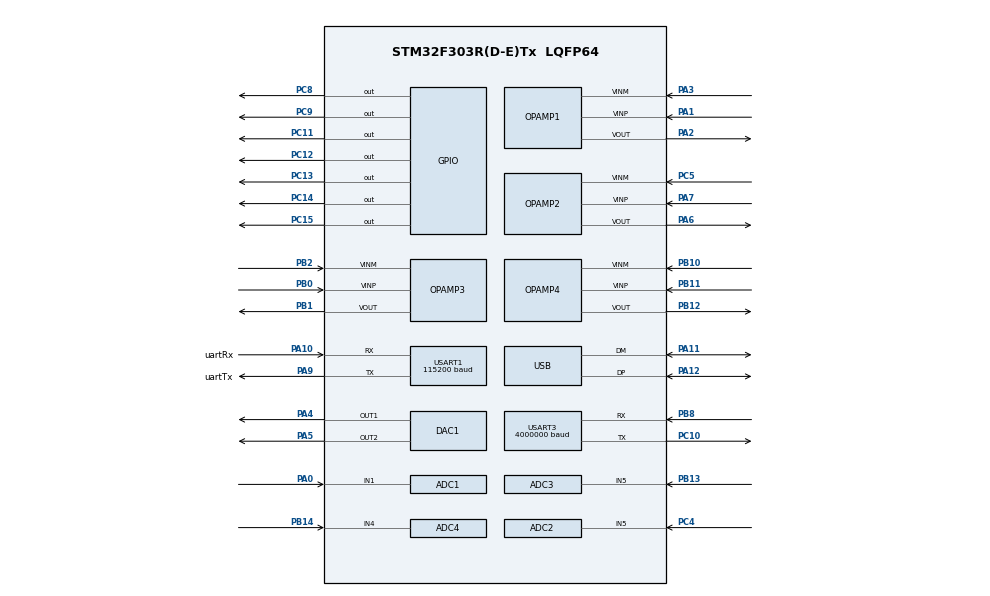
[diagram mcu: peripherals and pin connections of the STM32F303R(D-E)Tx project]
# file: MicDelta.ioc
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ADC1.AWD1HighThreshold=2500
ADC1.AWD1ITMode=ENABLE
ADC1.AWD1LowThreshold=1500
ADC1.Channel-0\#ChannelRegularConversion=ADC_CHANNEL_3
ADC1.ClockPrescaler=ADC_CLOCK_SYNC_PCLK_DIV1
ADC1.ContinuousConvMode=DISABLE
ADC1.DMAContinuousRequests=ENABLE
ADC1.DataAlign=ADC_DATAALIGN_RIGHT
ADC1.DiscontinuousConvMode=DISABLE
ADC1.EOCSelection=ADC_EOC_SINGLE_CONV
ADC1.EnableAnalogWatchDog1=true
ADC1.EnableAnalogWatchDog2=false
ADC1.EnableAnalogWatchDog3=false
ADC1.EnableInjectedConversion=ENABLE
ADC1.EnableRegularConversion=ENABLE
ADC1.ExternalTrigConv=ADC_EXTERNALTRIGCONV_T3_TRGO
ADC1.ExternalTrigConvEdge=ADC_EXTERNALTRIGCONVEDGE_RISING
ADC1.InjNumberOfConversion=0
ADC1.LowPowerAutoWait=DISABLE
ADC1.NbrOfConversion=1
ADC1.NbrOfConversionFlag=1
ADC1.Offset-0\#ChannelRegularConversion=0
ADC1.OffsetNumber-0\#ChannelRegularConversion=ADC_OFFSET_NONE
ADC1.Overrun=ADC_OVR_DATA_OVERWRITTEN
ADC1.Rank-0\#ChannelRegularConversion=1
ADC1.Resolution=ADC_RESOLUTION_12B
ADC1.SamplingTime-0\#ChannelRegularConversion=ADC_SAMPLETIME_61CYCLES_5
ADC1.ScanConvMode=ADC_SCAN_DISABLE
ADC1.WatchdogChannel=ADC_CHANNEL_3
ADC1.WatchdogMode=ADC_ANALOGWATCHDOG_SINGLE_REG
ADC1.master=1
ADC2.AWD1HighThreshold=2500
ADC2.AWD1ITMode=ENABLE
ADC2.AWD1LowThreshold=1500
ADC2.Channel-0\#ChannelRegularConversion=ADC_CHANNEL_3
ADC2.ClockPrescaler=ADC_CLOCK_SYNC_PCLK_DIV1
ADC2.ContinuousConvMode=DISABLE
ADC2.DMAContinuousRequests=ENABLE
ADC2.DataAlign=ADC_DATAALIGN_RIGHT
ADC2.DiscontinuousConvMode=DISABLE
ADC2.EOCSelection=ADC_EOC_SINGLE_CONV
ADC2.EnableAnalogWatchDog1=true
ADC2.EnableAnalogWatchDog2=false
ADC2.EnableAnalogWatchDog3=false
ADC2.EnableInjectedConversion=ENABLE
ADC2.EnableRegularConversion=ENABLE
ADC2.ExternalTrigConv=ADC_EXTERNALTRIGCONV_T3_TRGO
ADC2.ExternalTrigConvEdge=ADC_EXTERNALTRIGCONVEDGE_RISING
ADC2.InjNumberOfConversion=0
ADC2.LowPowerAutoWait=DISABLE
ADC2.NbrOfConversion=1
ADC2.NbrOfConversionFlag=1
ADC2.Offset-0\#ChannelRegularConversion=0
ADC2.OffsetNumber-0\#ChannelRegularConversion=ADC_OFFSET_NONE
ADC2.Overrun=ADC_OVR_DATA_OVERWRITTEN
ADC2.Rank-0\#ChannelRegularConversion=1
ADC2.Resolution=ADC_RESOLUTION_12B
ADC2.SamplingTime-0\#ChannelRegularConversion=ADC_SAMPLETIME_61CYCLES_5
ADC2.ScanConvMode=ADC_SCAN_DISABLE
ADC2.WatchdogChannel=ADC_CHANNEL_3
ADC2.WatchdogMode=ADC_ANALOGWATCHDOG_SINGLE_REG
ADC3.AWD1HighThreshold=2500
ADC3.AWD1ITMode=ENABLE
ADC3.AWD1LowThreshold=1500
ADC3.Channel-44\#ChannelRegularConversion=ADC_CHANNEL_1
ADC3.ClockPrescaler=ADC_CLOCK_SYNC_PCLK_DIV1
ADC3.ContinuousConvMode=DISABLE
ADC3.DMAContinuousRequests=ENABLE
ADC3.DataAlign=ADC_DATAALIGN_RIGHT
ADC3.DiscontinuousConvMode=DISABLE
ADC3.EOCSelection=ADC_EOC_SINGLE_CONV
ADC3.EnableAnalogWatchDog1=true
ADC3.EnableAnalogWatchDog2=false
ADC3.EnableAnalogWatchDog3=false
ADC3.EnableInjectedConversion=ENABLE
ADC3.EnableRegularConversion=ENABLE
ADC3.ExternalTrigConv=ADC_EXTERNALTRIGCONV_T3_TRGO
ADC3.ExternalTrigConvEdge=ADC_EXTERNALTRIGCONVEDGE_RISING
ADC3.InjNumberOfConversion=0
ADC3.LowPowerAutoWait=DISABLE
ADC3.NbrOfConversion=1
ADC3.NbrOfConversionFlag=1
ADC3.Offset-44\#ChannelRegularConversion=0
ADC3.OffsetNumber-44\#ChannelRegularConversion=ADC_OFFSET_NONE
ADC3.Overrun=ADC_OVR_DATA_OVERWRITTEN
ADC3.Rank-44\#ChannelRegularConversion=1
ADC3.Resolution=ADC_RESOLUTION_12B
ADC3.SamplingTime-44\#ChannelRegularConversion=ADC_SAMPLETIME_61CYCLES_5
ADC3.ScanConvMode=ADC_SCAN_DISABLE
ADC3.WatchdogChannel=ADC_CHANNEL_1
ADC3.WatchdogMode=ADC_ANALOGWATCHDOG_SINGLE_REG
ADC3.master=1
ADC4.AWD1HighThreshold=2500
ADC4.AWD1ITMode=ENABLE
ADC4.AWD1LowThreshold=1500
ADC4.Channel-56\#ChannelRegularConversion=ADC_CHANNEL_3
ADC4.ClockPrescaler=ADC_CLOCK_SYNC_PCLK_DIV1
ADC4.ContinuousConvMode=DISABLE
ADC4.DMAContinuousRequests=ENABLE
ADC4.DataAlign=ADC_DATAALIGN_RIGHT
ADC4.DiscontinuousConvMode=DISABLE
ADC4.EOCSelection=ADC_EOC_SINGLE_CONV
ADC4.EnableAnalogWatchDog1=true
ADC4.EnableAnalogWatchDog2=false
ADC4.EnableAnalogWatchDog3=false
ADC4.EnableInjectedConversion=ENABLE
ADC4.EnableRegularConversion=ENABLE
ADC4.ExternalTrigConv=ADC_EXTERNALTRIGCONV_T3_TRGO
ADC4.ExternalTrigConvEdge=ADC_EXTERNALTRIGCONVEDGE_RISING
ADC4.InjNumberOfConversion=0
ADC4.LowPowerAutoWait=DISABLE
ADC4.NbrOfConversion=1
ADC4.NbrOfConversionFlag=1
ADC4.Offset-56\#ChannelRegularConversion=0
ADC4.OffsetNumber-56\#ChannelRegularConversion=ADC_OFFSET_NONE
ADC4.Overrun=ADC_OVR_DATA_OVERWRITTEN
ADC4.Rank-56\#ChannelRegularConversion=1
ADC4.Resolution=ADC_RESOLUTION_12B
ADC4.SamplingTime-56\#ChannelRegularConversion=ADC_SAMPLETIME_61CYCLES_5
ADC4.ScanConvMode=ADC_SCAN_DISABLE
ADC4.WatchdogChannel=ADC_CHANNEL_3
ADC4.WatchdogMode=ADC_ANALOGWATCHDOG_SINGLE_REG
ARM.CMSIS.5.6.0.CMSISJjDSP=Library
Dma.ADC1.7.Direction=DMA_PERIPH_TO_MEMORY
Dma.ADC1.7.Instance=DMA1_Channel1
Dma.ADC1.7.MemDataAlignment=DMA_MDATAALIGN_HALFWORD
Dma.ADC1.7.MemInc=DMA_MINC_ENABLE
Dma.ADC1.7.Mode=DMA_CIRCULAR
Dma.ADC1.7.PeriphDataAlignment=DMA_PDATAALIGN_HALFWORD
Dma.ADC1.7.PeriphInc=DMA_PINC_DISABLE
Dma.ADC1.7.Priority=DMA_PRIORITY_MEDIUM
Dma.ADC2.5.Direction=DMA_PERIPH_TO_MEMORY
Dma.ADC2.5.Instance=DMA2_Channel1
Dma.ADC2.5.MemDataAlignment=DMA_MDATAALIGN_HALFWORD
Dma.ADC2.5.MemInc=DMA_MINC_ENABLE
Dma.ADC2.5.Mode=DMA_CIRCULAR
Dma.ADC2.5.PeriphDataAlignment=DMA_PDATAALIGN_HALFWORD
Dma.ADC2.5.PeriphInc=DMA_PINC_DISABLE
Dma.ADC2.5.Priority=DMA_PRIORITY_MEDIUM
Dma.ADC3.4.Direction=DMA_PERIPH_TO_MEMORY
Dma.ADC3.4.Instance=DMA2_Channel5
Dma.ADC3.4.MemDataAlignment=DMA_MDATAALIGN_HALFWORD
Dma.ADC3.4.MemInc=DMA_MINC_ENABLE
Dma.ADC3.4.Mode=DMA_CIRCULAR
Dma.ADC3.4.PeriphDataAlignment=DMA_PDATAALIGN_HALFWORD
Dma.ADC3.4.PeriphInc=DMA_PINC_DISABLE
Dma.ADC3.4.Priority=DMA_PRIORITY_MEDIUM
Dma.ADC4.3.Direction=DMA_PERIPH_TO_MEMORY
Dma.ADC4.3.Instance=DMA2_Channel2
Dma.ADC4.3.MemDataAlignment=DMA_MDATAALIGN_HALFWORD
Dma.ADC4.3.MemInc=DMA_MINC_ENABLE
Dma.ADC4.3.Mode=DMA_CIRCULAR
Dma.ADC4.3.PeriphDataAlignment=DMA_PDATAALIGN_HALFWORD
Dma.ADC4.3.PeriphInc=DMA_PINC_DISABLE
Dma.ADC4.3.Priority=DMA_PRIORITY_MEDIUM
Dma.MEMTOMEM.0.Direction=DMA_MEMORY_TO_MEMORY
Dma.MEMTOMEM.0.Instance=DMA1_Channel3
Dma.MEMTOMEM.0.MemDataAlignment=DMA_MDATAALIGN_BYTE
Dma.MEMTOMEM.0.MemInc=DMA_MINC_ENABLE
Dma.MEMTOMEM.0.Mode=DMA_NORMAL
Dma.MEMTOMEM.0.PeriphDataAlignment=DMA_PDATAALIGN_BYTE
Dma.MEMTOMEM.0.PeriphInc=DMA_PINC_ENABLE
Dma.MEMTOMEM.0.Priority=DMA_PRIORITY_LOW
Dma.Request0=MEMTOMEM
Dma.Request1=USART1_TX
Dma.Request2=USART1_RX
Dma.Request3=ADC4
Dma.Request4=ADC3
Dma.Request5=ADC2
Dma.Request6=TIM4_UP
Dma.Request7=ADC1
Dma.Request8=USART3_TX
Dma.TIM4_UP.6.Direction=DMA_MEMORY_TO_PERIPH
Dma.TIM4_UP.6.Instance=DMA1_Channel7
Dma.TIM4_UP.6.MemDataAlignment=DMA_MDATAALIGN_BYTE
Dma.TIM4_UP.6.MemInc=DMA_MINC_ENABLE
Dma.TIM4_UP.6.Mode=DMA_NORMAL
Dma.TIM4_UP.6.PeriphDataAlignment=DMA_PDATAALIGN_BYTE
Dma.TIM4_UP.6.PeriphInc=DMA_PINC_DISABLE
Dma.TIM4_UP.6.Priority=DMA_PRIORITY_VERY_HIGH
Dma.USART1_RX.2.Direction=DMA_PERIPH_TO_MEMORY
Dma.USART1_RX.2.Instance=DMA1_Channel5
Dma.USART1_RX.2.MemDataAlignment=DMA_MDATAALIGN_BYTE
Dma.USART1_RX.2.MemInc=DMA_MINC_ENABLE
Dma.USART1_RX.2.Mode=DMA_CIRCULAR
Dma.USART1_RX.2.PeriphDataAlignment=DMA_PDATAALIGN_BYTE
Dma.USART1_RX.2.PeriphInc=DMA_PINC_DISABLE
Dma.USART1_RX.2.Priority=DMA_PRIORITY_LOW
Dma.USART1_TX.1.Direction=DMA_MEMORY_TO_PERIPH
Dma.USART1_TX.1.Instance=DMA1_Channel4
Dma.USART1_TX.1.MemDataAlignment=DMA_MDATAALIGN_BYTE
Dma.USART1_TX.1.MemInc=DMA_MINC_ENABLE
Dma.USART1_TX.1.Mode=DMA_NORMAL
Dma.USART1_TX.1.PeriphDataAlignment=DMA_PDATAALIGN_BYTE
Dma.USART1_TX.1.PeriphInc=DMA_PINC_DISABLE
Dma.USART1_TX.1.Priority=DMA_PRIORITY_LOW
Dma.USART3_TX.8.Direction=DMA_MEMORY_TO_PERIPH
Dma.USART3_TX.8.Instance=DMA1_Channel2
Dma.USART3_TX.8.MemDataAlignment=DMA_MDATAALIGN_BYTE
Dma.USART3_TX.8.MemInc=DMA_MINC_ENABLE
Dma.USART3_TX.8.Mode=DMA_NORMAL
Dma.USART3_TX.8.PeriphDataAlignment=DMA_PDATAALIGN_BYTE
Dma.USART3_TX.8.PeriphInc=DMA_PINC_DISABLE
Dma.USART3_TX.8.Priority=DMA_PRIORITY_HIGH
Mcu.Family=STM32F3
Mcu.Name=STM32F303R(D-E)Tx
Mcu.Package=LQFP64
NVIC.ADC1_2_IRQn=true\:0\:0\:false\:false\:true\:true\:true
NVIC.ADC3_IRQn=true\:0\:0\:false\:false\:true\:true\:true
NVIC.ADC4_IRQn=true\:0\:0\:false\:false\:true\:true\:true
NVIC.DMA1_Channel1_IRQn=true\:0\:0\:false\:false\:true\:false\:true
NVIC.DMA1_Channel2_IRQn=true\:0\:0\:false\:false\:true\:false\:true
NVIC.DMA1_Channel4_IRQn=true\:0\:0\:false\:false\:true\:false\:true
NVIC.DMA1_Channel5_IRQn=true\:0\:0\:false\:false\:true\:false\:true
NVIC.DMA1_Channel7_IRQn=true\:0\:0\:false\:false\:true\:false\:true
NVIC.DMA2_Channel1_IRQn=true\:0\:0\:false\:false\:true\:false\:true
NVIC.DMA2_Channel2_IRQn=true\:0\:0\:false\:false\:true\:false\:true
NVIC.DMA2_Channel5_IRQn=true\:0\:0\:false\:false\:true\:false\:true
NVIC.PriorityGroup=NVIC_PRIORITYGROUP_4
NVIC.TIM2_IRQn=true\:0\:0\:false\:false\:true\:true\:true
NVIC.USART1_IRQn=true\:0\:0\:false\:false\:true\:true\:true
NVIC.USB_LP_CAN_RX0_IRQn=true\:0\:0\:false\:false\:true\:false\:true
OPAMP1.PgaGain=OPAMP_PGA_GAIN_16
OPAMP2.PgaGain=OPAMP_PGA_GAIN_16
OPAMP3.PgaGain=OPAMP_PGA_GAIN_16
OPAMP4.PgaGain=OPAMP_PGA_GAIN_16
PA0.Mode=IN1-Single-Ended
PA0.Signal=ADC1_IN1
PA1.Mode=PGA Connected
PA1.Signal=OPAMP1_VINP
PA10.GPIO_Label=uartRx
PA10.Mode=Asynchronous
PA10.Signal=USART1_RX
PA11.Mode=Device
PA11.Signal=USB_DM
PA12.Mode=Device
PA12.Signal=USB_DP
PA13.Mode=Serial_Wire
PA13.Signal=SYS_JTMS-SWDIO
PA14.Mode=Serial_Wire
PA14.Signal=SYS_JTCK-SWCLK
PA2.Mode=PGA Connected
PA2.Signal=OPAMP1_VOUT
PA3.Mode=PGA Connected
PA3.Signal=OPAMP1_VINM
PA4.Signal=COMP_DAC11_group
PA5.Signal=COMP_DAC12_group
PA6.GPIO_Mode=GPIO_MODE_ANALOG
PA6.Mode=PGA Connected
PA6.Signal=OPAMP2_VOUT
PA7.Mode=PGA Connected
PA7.Signal=OPAMP2_VINP
PA9.GPIO_Label=uartTx
PA9.Mode=Asynchronous
PA9.Signal=USART1_TX
PB0.Mode=PGA Connected
PB0.Signal=OPAMP3_VINP
PB1.Mode=PGA Connected
PB1.Signal=OPAMP3_VOUT
PB10.Mode=PGA Connected
PB10.Signal=OPAMP4_VINM
PB11.Mode=PGA Connected
PB11.Signal=OPAMP4_VINP
PB12.Mode=PGA Connected
PB12.Signal=OPAMP4_VOUT
PB13.Mode=IN5-Single-Ended
PB13.Signal=ADC3_IN5
PB14.Mode=IN4-Single-Ended
PB14.Signal=ADC4_IN4
PB2.Mode=PGA Connected
PB2.Signal=OPAMP3_VINM
PB8.Mode=Asynchronous
PB8.Signal=USART3_RX
PC10.GPIO_Speed=GPIO_SPEED_FREQ_MEDIUM
PC10.Mode=Asynchronous
PC10.Signal=USART3_TX
PC11.Signal=GPIO_Output
PC12.Signal=GPIO_Output
PC13.Signal=GPIO_Output
PC14-OSC32_IN.Signal=GPIO_Output
PC15-OSC32_OUT.Signal=GPIO_Output
PC4.Mode=IN5-Single-Ended
PC4.Signal=ADC2_IN5
PC5.Mode=PGA Connected
PC5.Signal=OPAMP2_VINM
PC8.Signal=GPIO_Output
PC9.Signal=GPIO_Output
PF0-OSC_IN.Mode=HSE-External-Oscillator
PF0-OSC_IN.Signal=RCC_OSC_IN
PF1-OSC_OUT.Mode=HSE-External-Oscillator
PF1-OSC_OUT.Signal=RCC_OSC_OUT
ProjectManager.HeapSize=0x200
ProjectManager.StackSize=0x800
ProjectManager.TargetToolchain=STM32CubeIDE
RCC.AHBFreq_Value=72000000
RCC.APB1CLKDivider=RCC_HCLK_DIV2
RCC.APB1Freq_Value=36000000
RCC.APB1TimFreq_Value=72000000
RCC.APB2Freq_Value=72000000
RCC.APB2TimFreq_Value=72000000
RCC.CortexFreq_Value=72000000
RCC.HCLKFreq_Value=72000000
RCC.HSE_VALUE=8000000
RCC.HSI_VALUE=8000000
RCC.LSE_VALUE=32768
RCC.PLLMUL=RCC_PLL_MUL9
RCC.PRESCALERUSB=RCC_USBCLKSOURCE_PLL_DIV1_5
RCC.SYSCLKFreq_VALUE=72000000
RCC.SYSCLKSourceVirtual=RCC_SYSCLKSOURCE_PLLCLK
RCC.USBFreq_Value=48000000
RCC.Uart4ClockSelection=RCC_UART4CLKSOURCE_SYSCLK
RCC.Uart5ClockSelection=RCC_UART5CLKSOURCE_SYSCLK
RCC.Usart3ClockSelection=RCC_USART3CLKSOURCE_SYSCLK
SH.COMP_DAC11_group.0=DAC1_OUT1,DAC_OUT1
SH.COMP_DAC12_group.0=DAC1_OUT2,Enable_DAC_OUT2
TIM2.AutoReloadPreload=TIM_AUTORELOAD_PRELOAD_ENABLE
TIM2.Period=0xffffffff
TIM2.Prescaler=71
TIM2.TIM_MasterOutputTrigger=TIM_TRGO_UPDATE
TIM3.AutoReloadPreload=TIM_AUTORELOAD_PRELOAD_ENABLE
TIM3.Period=719
TIM3.TIM_MasterOutputTrigger=TIM_TRGO_UPDATE
TIM4.AutoReloadPreload=TIM_AUTORELOAD_PRELOAD_ENABLE
TIM4.Period=28
TIM4.TIM_MasterOutputTrigger=TIM_TRGO_UPDATE
USART1.BaudRate=115200
USART1.VirtualMode-Asynchronous=VM_ASYNC
USART1.WordLength=WORDLENGTH_8B
USART3.BaudRate=4000000
USART3.Mode=MODE_TX
USART3.TxPinLevelInvertParam=ADVFEATURE_TXINV_ENABLE
USART3.VirtualMode-Asynchronous=VM_ASYNC
USB_DEVICE.CLASS_NAME_FS=CDC
USB_DEVICE.VirtualMode=Cdc
USB_DEVICE.VirtualModeFS=Cdc_FS
VP_ADC1_OPAMP_OUT1.Mode=IN3-OPAMP1-Single-Ended
VP_ADC2_OPAMP_OUT2.Mode=IN3-OPAMP2-Single-Ended
VP_ADC3_OPAMP_OUT3.Mode=IN1-OPAMP3-Single-Ended
VP_ADC4_OPAMP_OUT4.Mode=IN3-OPAMP4-Single-Ended
VP_ARM.CMSIS_VS_CMSISJjDSP_1.7.0_5.6.0.Mode=CMSISJjDSP
VP_TIM2_VS_ClockSourceINT.Mode=Internal
VP_TIM3_VS_ClockSourceINT.Mode=Internal
VP_TIM4_VS_ClockSourceINT.Mode=Internal
VP_USB_DEVICE_VS_USB_DEVICE_CDC_FS.Mode=CDC_FS
board=controller

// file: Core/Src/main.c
/* USER CODE BEGIN Header */
/**
  ******************************************************************************
  * @file           : main.c
  * @brief          : Main program body
  ******************************************************************************
  * @attention
  *
  * Copyright (c) 2022 STMicroelectronics.
  * All rights reserved.
  *
  * This software is licensed under terms that can be found in the LICENSE file
  * in the root directory of this software component.
  * If no LICENSE file comes with this software, it is provided AS-IS.
  *
  ******************************************************************************
  */
/* USER CODE END Header */
#include "main.h"
#include "usb_device.h"

ADC_HandleTypeDef hadc1;
ADC_HandleTypeDef hadc2;
ADC_HandleTypeDef hadc3;
ADC_HandleTypeDef hadc4;
DMA_HandleTypeDef hdma_adc1;
DMA_HandleTypeDef hdma_adc2;
DMA_HandleTypeDef hdma_adc3;
DMA_HandleTypeDef hdma_adc4;

OPAMP_HandleTypeDef hopamp1;
OPAMP_HandleTypeDef hopamp2;
OPAMP_HandleTypeDef hopamp3;
OPAMP_HandleTypeDef hopamp4;

void SystemClock_Config(void);
static void MX_GPIO_Init(void);
static void MX_DMA_Init(void);
static void MX_OPAMP2_Init(void);
static void MX_ADC2_Init(void);
static void MX_TIM3_Init(void);
static void MX_OPAMP4_Init(void);
static void MX_ADC4_Init(void);
static void MX_DAC1_Init(void);
static void MX_OPAMP3_Init(void);
static void MX_ADC1_Init(void);
static void MX_ADC3_Init(void);
static void MX_USART1_UART_Init(void);
static void MX_TIM2_Init(void);
static void MX_TIM4_Init(void);
static void MX_OPAMP1_Init(void);
static void MX_USART3_UART_Init(void);

int main(void)
{

  /* MCU Configuration--------------------------------------------------------*/

  /* Reset of all peripherals, Initializes the Flash interface and the Systick. */
  HAL_Init();

  /* Configure the system clock */
  SystemClock_Config();

  /* Initialize all configured peripherals */
  MX_GPIO_Init();
  MX_DMA_Init();
  MX_OPAMP2_Init();
  MX_ADC2_Init();
  MX_TIM3_Init();
  MX_OPAMP4_Init();
  MX_ADC4_Init();
  MX_DAC1_Init();
  MX_OPAMP3_Init();
  MX_ADC1_Init();
  MX_ADC3_Init();
  MX_USART1_UART_Init();
  MX_TIM2_Init();
  MX_USB_DEVICE_Init();
  MX_TIM4_Init();
  MX_OPAMP1_Init();
  MX_USART3_UART_Init();
  /* USER CODE BEGIN 2 */

  appMain(); //never returns!

  /* USER CODE END 2 */

  /* Infinite loop */

}

void SystemClock_Config(void)
{
  LL_FLASH_SetLatency(LL_FLASH_LATENCY_2);
  while(LL_FLASH_GetLatency()!= LL_FLASH_LATENCY_2)
  {
  }
  LL_RCC_HSE_Enable();

   /* Wait till HSE is ready */
  while(LL_RCC_HSE_IsReady() != 1)
  {

  }
  LL_RCC_PLL_ConfigDomain_SYS(LL_RCC_PLLSOURCE_HSE, LL_RCC_PLL_MUL_9, LL_RCC_PREDIV_DIV_1);
  LL_RCC_PLL_Enable();

   /* Wait till PLL is ready */
  while(LL_RCC_PLL_IsReady() != 1)
  {

  }
  LL_RCC_SetAHBPrescaler(LL_RCC_SYSCLK_DIV_1);
  LL_RCC_SetAPB1Prescaler(LL_RCC_APB1_DIV_2);
  LL_RCC_SetAPB2Prescaler(LL_RCC_APB2_DIV_1);
  LL_RCC_SetSysClkSource(LL_RCC_SYS_CLKSOURCE_PLL);

   /* Wait till System clock is ready */
  while(LL_RCC_GetSysClkSource() != LL_RCC_SYS_CLKSOURCE_STATUS_PLL)
  {

  }
  LL_SetSystemCoreClock(72000000);

   /* Update the time base */
  if (HAL_InitTick (TICK_INT_PRIORITY) != HAL_OK)
  {
    Error_Handler();
  }
  LL_RCC_SetUSARTClockSource(LL_RCC_USART1_CLKSOURCE_PCLK2);
  LL_RCC_SetUSARTClockSource(LL_RCC_USART3_CLKSOURCE_SYSCLK);
  LL_RCC_SetTIMClockSource(LL_RCC_TIM2_CLKSOURCE_PCLK1);
  LL_RCC_SetTIMClockSource(LL_RCC_TIM34_CLKSOURCE_PCLK1);
  LL_RCC_SetUSBClockSource(LL_RCC_USB_CLKSOURCE_PLL_DIV_1_5);
}

static void MX_ADC1_Init(void)
{

  ADC_MultiModeTypeDef multimode = {0};
  ADC_AnalogWDGConfTypeDef AnalogWDGConfig = {0};
  ADC_ChannelConfTypeDef sConfig = {0};

  /** Common config
  */
  hadc1.Instance = ADC1;
  hadc1.Init.ClockPrescaler = ADC_CLOCK_SYNC_PCLK_DIV1;
  hadc1.Init.Resolution = ADC_RESOLUTION_12B;
  hadc1.Init.ScanConvMode = ADC_SCAN_DISABLE;
  hadc1.Init.ContinuousConvMode = DISABLE;
  hadc1.Init.DiscontinuousConvMode = DISABLE;
  hadc1.Init.ExternalTrigConvEdge = ADC_EXTERNALTRIGCONVEDGE_RISING;
  hadc1.Init.ExternalTrigConv = ADC_EXTERNALTRIGCONV_T3_TRGO;
  hadc1.Init.DataAlign = ADC_DATAALIGN_RIGHT;
  hadc1.Init.NbrOfConversion = 1;
  hadc1.Init.DMAContinuousRequests = ENABLE;
  hadc1.Init.EOCSelection = ADC_EOC_SINGLE_CONV;
  hadc1.Init.LowPowerAutoWait = DISABLE;
  hadc1.Init.Overrun = ADC_OVR_DATA_OVERWRITTEN;
  if (HAL_ADC_Init(&hadc1) != HAL_OK)
  {
    Error_Handler();
  }
  /** Configure the ADC multi-mode
  */
  multimode.Mode = ADC_MODE_INDEPENDENT;
  if (HAL_ADCEx_MultiModeConfigChannel(&hadc1, &multimode) != HAL_OK)
  {
    Error_Handler();
  }
  /** Configure Analog WatchDog 1
  */
  AnalogWDGConfig.WatchdogNumber = ADC_ANALOGWATCHDOG_1;
  AnalogWDGConfig.WatchdogMode = ADC_ANALOGWATCHDOG_SINGLE_REG;
  AnalogWDGConfig.HighThreshold = 2500;
  AnalogWDGConfig.LowThreshold = 1500;
  AnalogWDGConfig.Channel = ADC_CHANNEL_3;
  AnalogWDGConfig.ITMode = ENABLE;
  if (HAL_ADC_AnalogWDGConfig(&hadc1, &AnalogWDGConfig) != HAL_OK)
  {
    Error_Handler();
  }
  /** Configure Regular Channel
  */
  sConfig.Channel = ADC_CHANNEL_3;
  sConfig.Rank = ADC_REGULAR_RANK_1;
  sConfig.SingleDiff = ADC_SINGLE_ENDED;
  sConfig.SamplingTime = ADC_SAMPLETIME_61CYCLES_5;
  sConfig.OffsetNumber = ADC_OFFSET_NONE;
  sConfig.Offset = 0;
  if (HAL_ADC_ConfigChannel(&hadc1, &sConfig) != HAL_OK)
  {
    Error_Handler();
  }

}

static void MX_ADC2_Init(void)
{

  ADC_AnalogWDGConfTypeDef AnalogWDGConfig = {0};
  ADC_ChannelConfTypeDef sConfig = {0};

  /** Common config
  */
  hadc2.Instance = ADC2;
  hadc2.Init.ClockPrescaler = ADC_CLOCK_SYNC_PCLK_DIV1;
  hadc2.Init.Resolution = ADC_RESOLUTION_12B;
  hadc2.Init.ScanConvMode = ADC_SCAN_DISABLE;
  hadc2.Init.ContinuousConvMode = DISABLE;
  hadc2.Init.DiscontinuousConvMode = DISABLE;
  hadc2.Init.ExternalTrigConvEdge = ADC_EXTERNALTRIGCONVEDGE_RISING;
  hadc2.Init.ExternalTrigConv = ADC_EXTERNALTRIGCONV_T3_TRGO;
  hadc2.Init.DataAlign = ADC_DATAALIGN_RIGHT;
  hadc2.Init.NbrOfConversion = 1;
  hadc2.Init.DMAContinuousRequests = ENABLE;
  hadc2.Init.EOCSelection = ADC_EOC_SINGLE_CONV;
  hadc2.Init.LowPowerAutoWait = DISABLE;
  hadc2.Init.Overrun = ADC_OVR_DATA_OVERWRITTEN;
  if (HAL_ADC_Init(&hadc2) != HAL_OK)
  {
    Error_Handler();
  }
  /** Configure Analog WatchDog 1
  */
  AnalogWDGConfig.WatchdogNumber = ADC_ANALOGWATCHDOG_1;
  AnalogWDGConfig.WatchdogMode = ADC_ANALOGWATCHDOG_SINGLE_REG;
  AnalogWDGConfig.HighThreshold = 2500;
  AnalogWDGConfig.LowThreshold = 1500;
  AnalogWDGConfig.Channel = ADC_CHANNEL_3;
  AnalogWDGConfig.ITMode = ENABLE;
  if (HAL_ADC_AnalogWDGConfig(&hadc2, &AnalogWDGConfig) != HAL_OK)
  {
    Error_Handler();
  }
  /** Configure Regular Channel
  */
  sConfig.Channel = ADC_CHANNEL_3;
  sConfig.Rank = ADC_REGULAR_RANK_1;
  sConfig.SingleDiff = ADC_SINGLE_ENDED;
  sConfig.SamplingTime = ADC_SAMPLETIME_61CYCLES_5;
  sConfig.OffsetNumber = ADC_OFFSET_NONE;
  sConfig.Offset = 0;
  if (HAL_ADC_ConfigChannel(&hadc2, &sConfig) != HAL_OK)
  {
    Error_Handler();
  }

}

static void MX_ADC3_Init(void)
{

  ADC_MultiModeTypeDef multimode = {0};
  ADC_AnalogWDGConfTypeDef AnalogWDGConfig = {0};
  ADC_ChannelConfTypeDef sConfig = {0};

  /** Common config
  */
  hadc3.Instance = ADC3;
  hadc3.Init.ClockPrescaler = ADC_CLOCK_SYNC_PCLK_DIV1;
  hadc3.Init.Resolution = ADC_RESOLUTION_12B;
  hadc3.Init.ScanConvMode = ADC_SCAN_DISABLE;
  hadc3.Init.ContinuousConvMode = DISABLE;
  hadc3.Init.DiscontinuousConvMode = DISABLE;
  hadc3.Init.ExternalTrigConvEdge = ADC_EXTERNALTRIGCONVEDGE_RISING;
  hadc3.Init.ExternalTrigConv = ADC_EXTERNALTRIGCONV_T3_TRGO;
  hadc3.Init.DataAlign = ADC_DATAALIGN_RIGHT;
  hadc3.Init.NbrOfConversion = 1;
  hadc3.Init.DMAContinuousRequests = ENABLE;
  hadc3.Init.EOCSelection = ADC_EOC_SINGLE_CONV;
  hadc3.Init.LowPowerAutoWait = DISABLE;
  hadc3.Init.Overrun = ADC_OVR_DATA_OVERWRITTEN;
  if (HAL_ADC_Init(&hadc3) != HAL_OK)
  {
    Error_Handler();
  }
  /** Configure the ADC multi-mode
  */
  multimode.Mode = ADC_MODE_INDEPENDENT;
  if (HAL_ADCEx_MultiModeConfigChannel(&hadc3, &multimode) != HAL_OK)
  {
    Error_Handler();
  }
  /** Configure Analog WatchDog 1
  */
  AnalogWDGConfig.WatchdogNumber = ADC_ANALOGWATCHDOG_1;
  AnalogWDGConfig.WatchdogMode = ADC_ANALOGWATCHDOG_SINGLE_REG;
  AnalogWDGConfig.HighThreshold = 2500;
  AnalogWDGConfig.LowThreshold = 1500;
  AnalogWDGConfig.Channel = ADC_CHANNEL_1;
  AnalogWDGConfig.ITMode = ENABLE;
  if (HAL_ADC_AnalogWDGConfig(&hadc3, &AnalogWDGConfig) != HAL_OK)
  {
    Error_Handler();
  }
  /** Configure Regular Channel
  */
  sConfig.Channel = ADC_CHANNEL_1;
  sConfig.Rank = ADC_REGULAR_RANK_1;
  sConfig.SingleDiff = ADC_SINGLE_ENDED;
  sConfig.SamplingTime = ADC_SAMPLETIME_61CYCLES_5;
  sConfig.OffsetNumber = ADC_OFFSET_NONE;
  sConfig.Offset = 0;
  if (HAL_ADC_ConfigChannel(&hadc3, &sConfig) != HAL_OK)
  {
    Error_Handler();
  }

}

static void MX_ADC4_Init(void)
{

  ADC_AnalogWDGConfTypeDef AnalogWDGConfig = {0};
  ADC_ChannelConfTypeDef sConfig = {0};

  /** Common config
  */
  hadc4.Instance = ADC4;
  hadc4.Init.ClockPrescaler = ADC_CLOCK_SYNC_PCLK_DIV1;
  hadc4.Init.Resolution = ADC_RESOLUTION_12B;
  hadc4.Init.ScanConvMode = ADC_SCAN_DISABLE;
  hadc4.Init.ContinuousConvMode = DISABLE;
  hadc4.Init.DiscontinuousConvMode = DISABLE;
  hadc4.Init.ExternalTrigConvEdge = ADC_EXTERNALTRIGCONVEDGE_RISING;
  hadc4.Init.ExternalTrigConv = ADC_EXTERNALTRIGCONV_T3_TRGO;
  hadc4.Init.DataAlign = ADC_DATAALIGN_RIGHT;
  hadc4.Init.NbrOfConversion = 1;
  hadc4.Init.DMAContinuousRequests = ENABLE;
  hadc4.Init.EOCSelection = ADC_EOC_SINGLE_CONV;
  hadc4.Init.LowPowerAutoWait = DISABLE;
  hadc4.Init.Overrun = ADC_OVR_DATA_OVERWRITTEN;
  if (HAL_ADC_Init(&hadc4) != HAL_OK)
  {
    Error_Handler();
  }
  /** Configure Analog WatchDog 1
  */
  AnalogWDGConfig.WatchdogNumber = ADC_ANALOGWATCHDOG_1;
  AnalogWDGConfig.WatchdogMode = ADC_ANALOGWATCHDOG_SINGLE_REG;
  AnalogWDGConfig.HighThreshold = 2500;
  AnalogWDGConfig.LowThreshold = 1500;
  AnalogWDGConfig.Channel = ADC_CHANNEL_3;
  AnalogWDGConfig.ITMode = ENABLE;
  if (HAL_ADC_AnalogWDGConfig(&hadc4, &AnalogWDGConfig) != HAL_OK)
  {
    Error_Handler();
  }
  /** Configure Regular Channel
  */
  sConfig.Channel = ADC_CHANNEL_3;
  sConfig.Rank = ADC_REGULAR_RANK_1;
  sConfig.SingleDiff = ADC_SINGLE_ENDED;
  sConfig.SamplingTime = ADC_SAMPLETIME_61CYCLES_5;
  sConfig.OffsetNumber = ADC_OFFSET_NONE;
  sConfig.Offset = 0;
  if (HAL_ADC_ConfigChannel(&hadc4, &sConfig) != HAL_OK)
  {
    Error_Handler();
  }

}

static void MX_DAC1_Init(void)
{

  LL_DAC_InitTypeDef DAC_InitStruct = {0};

  LL_GPIO_InitTypeDef GPIO_InitStruct = {0};

  /* Peripheral clock enable */
  LL_APB1_GRP1_EnableClock(LL_APB1_GRP1_PERIPH_DAC1);

  LL_AHB1_GRP1_EnableClock(LL_AHB1_GRP1_PERIPH_GPIOA);
  /**DAC1 GPIO Configuration
  PA4   ------> DAC1_OUT1
  PA5   ------> DAC1_OUT2
  */
  GPIO_InitStruct.Pin = LL_GPIO_PIN_4|LL_GPIO_PIN_5;
  GPIO_InitStruct.Mode = LL_GPIO_MODE_ANALOG;
  GPIO_InitStruct.Pull = LL_GPIO_PULL_NO;
  LL_GPIO_Init(GPIOA, &GPIO_InitStruct);

  /** DAC channel OUT1 config
  */
  DAC_InitStruct.TriggerSource = LL_DAC_TRIG_SOFTWARE;
  DAC_InitStruct.WaveAutoGeneration = LL_DAC_WAVE_AUTO_GENERATION_NONE;
  DAC_InitStruct.OutputBuffer = LL_DAC_OUTPUT_BUFFER_ENABLE;
  LL_DAC_Init(DAC1, LL_DAC_CHANNEL_1, &DAC_InitStruct);
  LL_DAC_DisableTrigger(DAC1, LL_DAC_CHANNEL_1);
  /** DAC channel OUT2 config
  */
  LL_DAC_Init(DAC1, LL_DAC_CHANNEL_2, &DAC_InitStruct);
  LL_DAC_DisableTrigger(DAC1, LL_DAC_CHANNEL_2);

}

static void MX_OPAMP1_Init(void)
{

  hopamp1.Instance = OPAMP1;
  hopamp1.Init.Mode = OPAMP_PGA_MODE;
  hopamp1.Init.NonInvertingInput = OPAMP_NONINVERTINGINPUT_IO0;
  hopamp1.Init.TimerControlledMuxmode = OPAMP_TIMERCONTROLLEDMUXMODE_DISABLE;
  hopamp1.Init.PgaConnect = OPAMP_PGA_CONNECT_INVERTINGINPUT_IO1;
  hopamp1.Init.PgaGain = OPAMP_PGA_GAIN_16;
  hopamp1.Init.UserTrimming = OPAMP_TRIMMING_FACTORY;
  if (HAL_OPAMP_Init(&hopamp1) != HAL_OK)
  {
    Error_Handler();
  }

}

static void MX_OPAMP2_Init(void)
{

  hopamp2.Instance = OPAMP2;
  hopamp2.Init.Mode = OPAMP_PGA_MODE;
  hopamp2.Init.NonInvertingInput = OPAMP_NONINVERTINGINPUT_IO0;
  hopamp2.Init.TimerControlledMuxmode = OPAMP_TIMERCONTROLLEDMUXMODE_DISABLE;
  hopamp2.Init.PgaConnect = OPAMP_PGA_CONNECT_INVERTINGINPUT_IO0;
  hopamp2.Init.PgaGain = OPAMP_PGA_GAIN_16;
  hopamp2.Init.UserTrimming = OPAMP_TRIMMING_FACTORY;
  if (HAL_OPAMP_Init(&hopamp2) != HAL_OK)
  {
    Error_Handler();
  }

}

static void MX_OPAMP3_Init(void)
{

  hopamp3.Instance = OPAMP3;
  hopamp3.Init.Mode = OPAMP_PGA_MODE;
  hopamp3.Init.NonInvertingInput = OPAMP_NONINVERTINGINPUT_IO0;
  hopamp3.Init.TimerControlledMuxmode = OPAMP_TIMERCONTROLLEDMUXMODE_DISABLE;
  hopamp3.Init.PgaConnect = OPAMP_PGA_CONNECT_INVERTINGINPUT_IO1;
  hopamp3.Init.PgaGain = OPAMP_PGA_GAIN_16;
  hopamp3.Init.UserTrimming = OPAMP_TRIMMING_FACTORY;
  if (HAL_OPAMP_Init(&hopamp3) != HAL_OK)
  {
    Error_Handler();
  }

}

static void MX_OPAMP4_Init(void)
{

  hopamp4.Instance = OPAMP4;
  hopamp4.Init.Mode = OPAMP_PGA_MODE;
  hopamp4.Init.NonInvertingInput = OPAMP_NONINVERTINGINPUT_IO3;
  hopamp4.Init.TimerControlledMuxmode = OPAMP_TIMERCONTROLLEDMUXMODE_DISABLE;
  hopamp4.Init.PgaConnect = OPAMP_PGA_CONNECT_INVERTINGINPUT_IO0;
  hopamp4.Init.PgaGain = OPAMP_PGA_GAIN_16;
  hopamp4.Init.UserTrimming = OPAMP_TRIMMING_FACTORY;
  if (HAL_OPAMP_Init(&hopamp4) != HAL_OK)
  {
    Error_Handler();
  }

}

static void MX_TIM2_Init(void)
{

  LL_TIM_InitTypeDef TIM_InitStruct = {0};

  /* Peripheral clock enable */
  LL_APB1_GRP1_EnableClock(LL_APB1_GRP1_PERIPH_TIM2);

  /* TIM2 interrupt Init */
  NVIC_SetPriority(TIM2_IRQn, NVIC_EncodePriority(NVIC_GetPriorityGrouping(),0, 0));
  NVIC_EnableIRQ(TIM2_IRQn);

  TIM_InitStruct.Prescaler = 71;
  TIM_InitStruct.CounterMode = LL_TIM_COUNTERMODE_UP;
  TIM_InitStruct.Autoreload = 0xffffffff;
  TIM_InitStruct.ClockDivision = LL_TIM_CLOCKDIVISION_DIV1;
  LL_TIM_Init(TIM2, &TIM_InitStruct);
  LL_TIM_EnableARRPreload(TIM2);
  LL_TIM_SetClockSource(TIM2, LL_TIM_CLOCKSOURCE_INTERNAL);
  LL_TIM_SetTriggerOutput(TIM2, LL_TIM_TRGO_UPDATE);
  LL_TIM_DisableMasterSlaveMode(TIM2);

}

static void MX_TIM3_Init(void)
{

  LL_TIM_InitTypeDef TIM_InitStruct = {0};

  /* Peripheral clock enable */
  LL_APB1_GRP1_EnableClock(LL_APB1_GRP1_PERIPH_TIM3);

  TIM_InitStruct.Prescaler = 0;
  TIM_InitStruct.CounterMode = LL_TIM_COUNTERMODE_UP;
  TIM_InitStruct.Autoreload = 719;
  TIM_InitStruct.ClockDivision = LL_TIM_CLOCKDIVISION_DIV1;
  LL_TIM_Init(TIM3, &TIM_InitStruct);
  LL_TIM_EnableARRPreload(TIM3);
  LL_TIM_SetClockSource(TIM3, LL_TIM_CLOCKSOURCE_INTERNAL);
  LL_TIM_SetTriggerOutput(TIM3, LL_TIM_TRGO_UPDATE);
  LL_TIM_DisableMasterSlaveMode(TIM3);

}

static void MX_TIM4_Init(void)
{

  LL_TIM_InitTypeDef TIM_InitStruct = {0};

  /* Peripheral clock enable */
  LL_APB1_GRP1_EnableClock(LL_APB1_GRP1_PERIPH_TIM4);

  /* TIM4 DMA Init */

  /* TIM4_UP Init */
  LL_DMA_SetDataTransferDirection(DMA1, LL_DMA_CHANNEL_7, LL_DMA_DIRECTION_MEMORY_TO_PERIPH);

  LL_DMA_SetChannelPriorityLevel(DMA1, LL_DMA_CHANNEL_7, LL_DMA_PRIORITY_VERYHIGH);

  LL_DMA_SetMode(DMA1, LL_DMA_CHANNEL_7, LL_DMA_MODE_NORMAL);

  LL_DMA_SetPeriphIncMode(DMA1, LL_DMA_CHANNEL_7, LL_DMA_PERIPH_NOINCREMENT);

  LL_DMA_SetMemoryIncMode(DMA1, LL_DMA_CHANNEL_7, LL_DMA_MEMORY_INCREMENT);

  LL_DMA_SetPeriphSize(DMA1, LL_DMA_CHANNEL_7, LL_DMA_PDATAALIGN_BYTE);

  LL_DMA_SetMemorySize(DMA1, LL_DMA_CHANNEL_7, LL_DMA_MDATAALIGN_BYTE);

  TIM_InitStruct.Prescaler = 0;
  TIM_InitStruct.CounterMode = LL_TIM_COUNTERMODE_UP;
  TIM_InitStruct.Autoreload = 28;
  TIM_InitStruct.ClockDivision = LL_TIM_CLOCKDIVISION_DIV1;
  LL_TIM_Init(TIM4, &TIM_InitStruct);
  LL_TIM_EnableARRPreload(TIM4);
  LL_TIM_SetClockSource(TIM4, LL_TIM_CLOCKSOURCE_INTERNAL);
  LL_TIM_SetTriggerOutput(TIM4, LL_TIM_TRGO_UPDATE);
  LL_TIM_DisableMasterSlaveMode(TIM4);

}

static void MX_USART1_UART_Init(void)
{

  LL_USART_InitTypeDef USART_InitStruct = {0};

  LL_GPIO_InitTypeDef GPIO_InitStruct = {0};

  /* Peripheral clock enable */
  LL_APB2_GRP1_EnableClock(LL_APB2_GRP1_PERIPH_USART1);

  LL_AHB1_GRP1_EnableClock(LL_AHB1_GRP1_PERIPH_GPIOA);
  /**USART1 GPIO Configuration
  PA9   ------> USART1_TX
  PA10   ------> USART1_RX
  */
  GPIO_InitStruct.Pin = uartTx_Pin|uartRx_Pin;
  GPIO_InitStruct.Mode = LL_GPIO_MODE_ALTERNATE;
  GPIO_InitStruct.Speed = LL_GPIO_SPEED_FREQ_HIGH;
  GPIO_InitStruct.OutputType = LL_GPIO_OUTPUT_PUSHPULL;
  GPIO_InitStruct.Pull = LL_GPIO_PULL_NO;
  GPIO_InitStruct.Alternate = LL_GPIO_AF_7;
  LL_GPIO_Init(GPIOA, &GPIO_InitStruct);

  /* USART1 DMA Init */

  /* USART1_TX Init */
  LL_DMA_SetDataTransferDirection(DMA1, LL_DMA_CHANNEL_4, LL_DMA_DIRECTION_MEMORY_TO_PERIPH);

  LL_DMA_SetChannelPriorityLevel(DMA1, LL_DMA_CHANNEL_4, LL_DMA_PRIORITY_LOW);

  LL_DMA_SetMode(DMA1, LL_DMA_CHANNEL_4, LL_DMA_MODE_NORMAL);

  LL_DMA_SetPeriphIncMode(DMA1, LL_DMA_CHANNEL_4, LL_DMA_PERIPH_NOINCREMENT);

  LL_DMA_SetMemoryIncMode(DMA1, LL_DMA_CHANNEL_4, LL_DMA_MEMORY_INCREMENT);

  LL_DMA_SetPeriphSize(DMA1, LL_DMA_CHANNEL_4, LL_DMA_PDATAALIGN_BYTE);

  LL_DMA_SetMemorySize(DMA1, LL_DMA_CHANNEL_4, LL_DMA_MDATAALIGN_BYTE);

  /* USART1_RX Init */
  LL_DMA_SetDataTransferDirection(DMA1, LL_DMA_CHANNEL_5, LL_DMA_DIRECTION_PERIPH_TO_MEMORY);

  LL_DMA_SetChannelPriorityLevel(DMA1, LL_DMA_CHANNEL_5, LL_DMA_PRIORITY_LOW);

  LL_DMA_SetMode(DMA1, LL_DMA_CHANNEL_5, LL_DMA_MODE_CIRCULAR);

  LL_DMA_SetPeriphIncMode(DMA1, LL_DMA_CHANNEL_5, LL_DMA_PERIPH_NOINCREMENT);

  LL_DMA_SetMemoryIncMode(DMA1, LL_DMA_CHANNEL_5, LL_DMA_MEMORY_INCREMENT);

  LL_DMA_SetPeriphSize(DMA1, LL_DMA_CHANNEL_5, LL_DMA_PDATAALIGN_BYTE);

  LL_DMA_SetMemorySize(DMA1, LL_DMA_CHANNEL_5, LL_DMA_MDATAALIGN_BYTE);

  /* USART1 interrupt Init */
  NVIC_SetPriority(USART1_IRQn, NVIC_EncodePriority(NVIC_GetPriorityGrouping(),0, 0));
  NVIC_EnableIRQ(USART1_IRQn);

  USART_InitStruct.BaudRate = 115200;
  USART_InitStruct.DataWidth = LL_USART_DATAWIDTH_8B;
  USART_InitStruct.StopBits = LL_USART_STOPBITS_1;
  USART_InitStruct.Parity = LL_USART_PARITY_NONE;
  USART_InitStruct.TransferDirection = LL_USART_DIRECTION_TX_RX;
  USART_InitStruct.HardwareFlowControl = LL_USART_HWCONTROL_NONE;
  USART_InitStruct.OverSampling = LL_USART_OVERSAMPLING_16;
  LL_USART_Init(USART1, &USART_InitStruct);
  LL_USART_DisableIT_CTS(USART1);
  LL_USART_ConfigAsyncMode(USART1);
  LL_USART_Enable(USART1);

}

static void MX_USART3_UART_Init(void)
{

  LL_USART_InitTypeDef USART_InitStruct = {0};

  LL_GPIO_InitTypeDef GPIO_InitStruct = {0};

  /* Peripheral clock enable */
  LL_APB1_GRP1_EnableClock(LL_APB1_GRP1_PERIPH_USART3);

  LL_AHB1_GRP1_EnableClock(LL_AHB1_GRP1_PERIPH_GPIOC);
  LL_AHB1_GRP1_EnableClock(LL_AHB1_GRP1_PERIPH_GPIOB);
  /**USART3 GPIO Configuration
  PC10   ------> USART3_TX
  PB8   ------> USART3_RX
  */
  GPIO_InitStruct.Pin = LL_GPIO_PIN_10;
  GPIO_InitStruct.Mode = LL_GPIO_MODE_ALTERNATE;
  GPIO_InitStruct.Speed = LL_GPIO_SPEED_FREQ_MEDIUM;
  GPIO_InitStruct.OutputType = LL_GPIO_OUTPUT_PUSHPULL;
  GPIO_InitStruct.Pull = LL_GPIO_PULL_NO;
  GPIO_InitStruct.Alternate = LL_GPIO_AF_7;
  LL_GPIO_Init(GPIOC, &GPIO_InitStruct);

  GPIO_InitStruct.Pin = LL_GPIO_PIN_8;
  GPIO_InitStruct.Mode = LL_GPIO_MODE_ALTERNATE;
  GPIO_InitStruct.Speed = LL_GPIO_SPEED_FREQ_HIGH;
  GPIO_InitStruct.OutputType = LL_GPIO_OUTPUT_PUSHPULL;
  GPIO_InitStruct.Pull = LL_GPIO_PULL_NO;
  GPIO_InitStruct.Alternate = LL_GPIO_AF_7;
  LL_GPIO_Init(GPIOB, &GPIO_InitStruct);

  /* USART3 DMA Init */

  /* USART3_TX Init */
  LL_DMA_SetDataTransferDirection(DMA1, LL_DMA_CHANNEL_2, LL_DMA_DIRECTION_MEMORY_TO_PERIPH);

  LL_DMA_SetChannelPriorityLevel(DMA1, LL_DMA_CHANNEL_2, LL_DMA_PRIORITY_HIGH);

  LL_DMA_SetMode(DMA1, LL_DMA_CHANNEL_2, LL_DMA_MODE_NORMAL);

  LL_DMA_SetPeriphIncMode(DMA1, LL_DMA_CHANNEL_2, LL_DMA_PERIPH_NOINCREMENT);

  LL_DMA_SetMemoryIncMode(DMA1, LL_DMA_CHANNEL_2, LL_DMA_MEMORY_INCREMENT);

  LL_DMA_SetPeriphSize(DMA1, LL_DMA_CHANNEL_2, LL_DMA_PDATAALIGN_BYTE);

  LL_DMA_SetMemorySize(DMA1, LL_DMA_CHANNEL_2, LL_DMA_MDATAALIGN_BYTE);

  USART_InitStruct.BaudRate = 4000000;
  USART_InitStruct.DataWidth = LL_USART_DATAWIDTH_8B;
  USART_InitStruct.StopBits = LL_USART_STOPBITS_1;
  USART_InitStruct.Parity = LL_USART_PARITY_NONE;
  USART_InitStruct.TransferDirection = LL_USART_DIRECTION_TX;
  USART_InitStruct.HardwareFlowControl = LL_USART_HWCONTROL_NONE;
  USART_InitStruct.OverSampling = LL_USART_OVERSAMPLING_16;
  LL_USART_Init(USART3, &USART_InitStruct);
  LL_USART_DisableIT_CTS(USART3);
  LL_USART_SetTXPinLevel(USART3, LL_USART_TXPIN_LEVEL_INVERTED);
  LL_USART_ConfigAsyncMode(USART3);
  LL_USART_Enable(USART3);

}

static void MX_DMA_Init(void)
{

  /* Init with LL driver */
  /* DMA controller clock enable */
  LL_AHB1_GRP1_EnableClock(LL_AHB1_GRP1_PERIPH_DMA1);
  LL_AHB1_GRP1_EnableClock(LL_AHB1_GRP1_PERIPH_DMA2);

  /* Configure DMA request MEMTOMEM_DMA1_Channel3 */

  /* Set transfer direction */
  LL_DMA_SetDataTransferDirection(DMA1, LL_DMA_CHANNEL_3, LL_DMA_DIRECTION_MEMORY_TO_MEMORY);

  /* Set priority level */
  LL_DMA_SetChannelPriorityLevel(DMA1, LL_DMA_CHANNEL_3, LL_DMA_PRIORITY_LOW);

  /* Set DMA mode */
  LL_DMA_SetMode(DMA1, LL_DMA_CHANNEL_3, LL_DMA_MODE_NORMAL);

  /* Set peripheral increment mode */
  LL_DMA_SetPeriphIncMode(DMA1, LL_DMA_CHANNEL_3, LL_DMA_PERIPH_INCREMENT);

  /* Set memory increment mode */
  LL_DMA_SetMemoryIncMode(DMA1, LL_DMA_CHANNEL_3, LL_DMA_MEMORY_INCREMENT);

  /* Set peripheral data width */
  LL_DMA_SetPeriphSize(DMA1, LL_DMA_CHANNEL_3, LL_DMA_PDATAALIGN_BYTE);

  /* Set memory data width */
  LL_DMA_SetMemorySize(DMA1, LL_DMA_CHANNEL_3, LL_DMA_MDATAALIGN_BYTE);

  /* DMA interrupt init */
  /* DMA1_Channel1_IRQn interrupt configuration */
  HAL_NVIC_SetPriority(DMA1_Channel1_IRQn, 0, 0);
  HAL_NVIC_EnableIRQ(DMA1_Channel1_IRQn);
  /* DMA1_Channel2_IRQn interrupt configuration */
  NVIC_SetPriority(DMA1_Channel2_IRQn, NVIC_EncodePriority(NVIC_GetPriorityGrouping(),0, 0));
  NVIC_EnableIRQ(DMA1_Channel2_IRQn);
  /* DMA1_Channel4_IRQn interrupt configuration */
  NVIC_SetPriority(DMA1_Channel4_IRQn, NVIC_EncodePriority(NVIC_GetPriorityGrouping(),0, 0));
  NVIC_EnableIRQ(DMA1_Channel4_IRQn);
  /* DMA1_Channel5_IRQn interrupt configuration */
  NVIC_SetPriority(DMA1_Channel5_IRQn, NVIC_EncodePriority(NVIC_GetPriorityGrouping(),0, 0));
  NVIC_EnableIRQ(DMA1_Channel5_IRQn);
  /* DMA1_Channel7_IRQn interrupt configuration */
  NVIC_SetPriority(DMA1_Channel7_IRQn, NVIC_EncodePriority(NVIC_GetPriorityGrouping(),0, 0));
  NVIC_EnableIRQ(DMA1_Channel7_IRQn);
  /* DMA2_Channel1_IRQn interrupt configuration */
  HAL_NVIC_SetPriority(DMA2_Channel1_IRQn, 0, 0);
  HAL_NVIC_EnableIRQ(DMA2_Channel1_IRQn);
  /* DMA2_Channel2_IRQn interrupt configuration */
  HAL_NVIC_SetPriority(DMA2_Channel2_IRQn, 0, 0);
  HAL_NVIC_EnableIRQ(DMA2_Channel2_IRQn);
  /* DMA2_Channel5_IRQn interrupt configuration */
  HAL_NVIC_SetPriority(DMA2_Channel5_IRQn, 0, 0);
  HAL_NVIC_EnableIRQ(DMA2_Channel5_IRQn);

}

static void MX_GPIO_Init(void)
{
  LL_GPIO_InitTypeDef GPIO_InitStruct = {0};

  /* GPIO Ports Clock Enable */
  LL_AHB1_GRP1_EnableClock(LL_AHB1_GRP1_PERIPH_GPIOC);
  LL_AHB1_GRP1_EnableClock(LL_AHB1_GRP1_PERIPH_GPIOF);
  LL_AHB1_GRP1_EnableClock(LL_AHB1_GRP1_PERIPH_GPIOA);
  LL_AHB1_GRP1_EnableClock(LL_AHB1_GRP1_PERIPH_GPIOB);

  /**/
  LL_GPIO_ResetOutputPin(GPIOC, LL_GPIO_PIN_13|LL_GPIO_PIN_14|LL_GPIO_PIN_15|LL_GPIO_PIN_8
                          |LL_GPIO_PIN_9|LL_GPIO_PIN_11|LL_GPIO_PIN_12);

  /**/
  GPIO_InitStruct.Pin = LL_GPIO_PIN_13|LL_GPIO_PIN_14|LL_GPIO_PIN_15|LL_GPIO_PIN_8
                          |LL_GPIO_PIN_9|LL_GPIO_PIN_11|LL_GPIO_PIN_12;
  GPIO_InitStruct.Mode = LL_GPIO_MODE_OUTPUT;
  GPIO_InitStruct.Speed = LL_GPIO_SPEED_FREQ_LOW;
  GPIO_InitStruct.OutputType = LL_GPIO_OUTPUT_PUSHPULL;
  GPIO_InitStruct.Pull = LL_GPIO_PULL_NO;
  LL_GPIO_Init(GPIOC, &GPIO_InitStruct);

}

void Error_Handler(void)
{
  __disable_irq();
  while (1)
  {
  }
}
